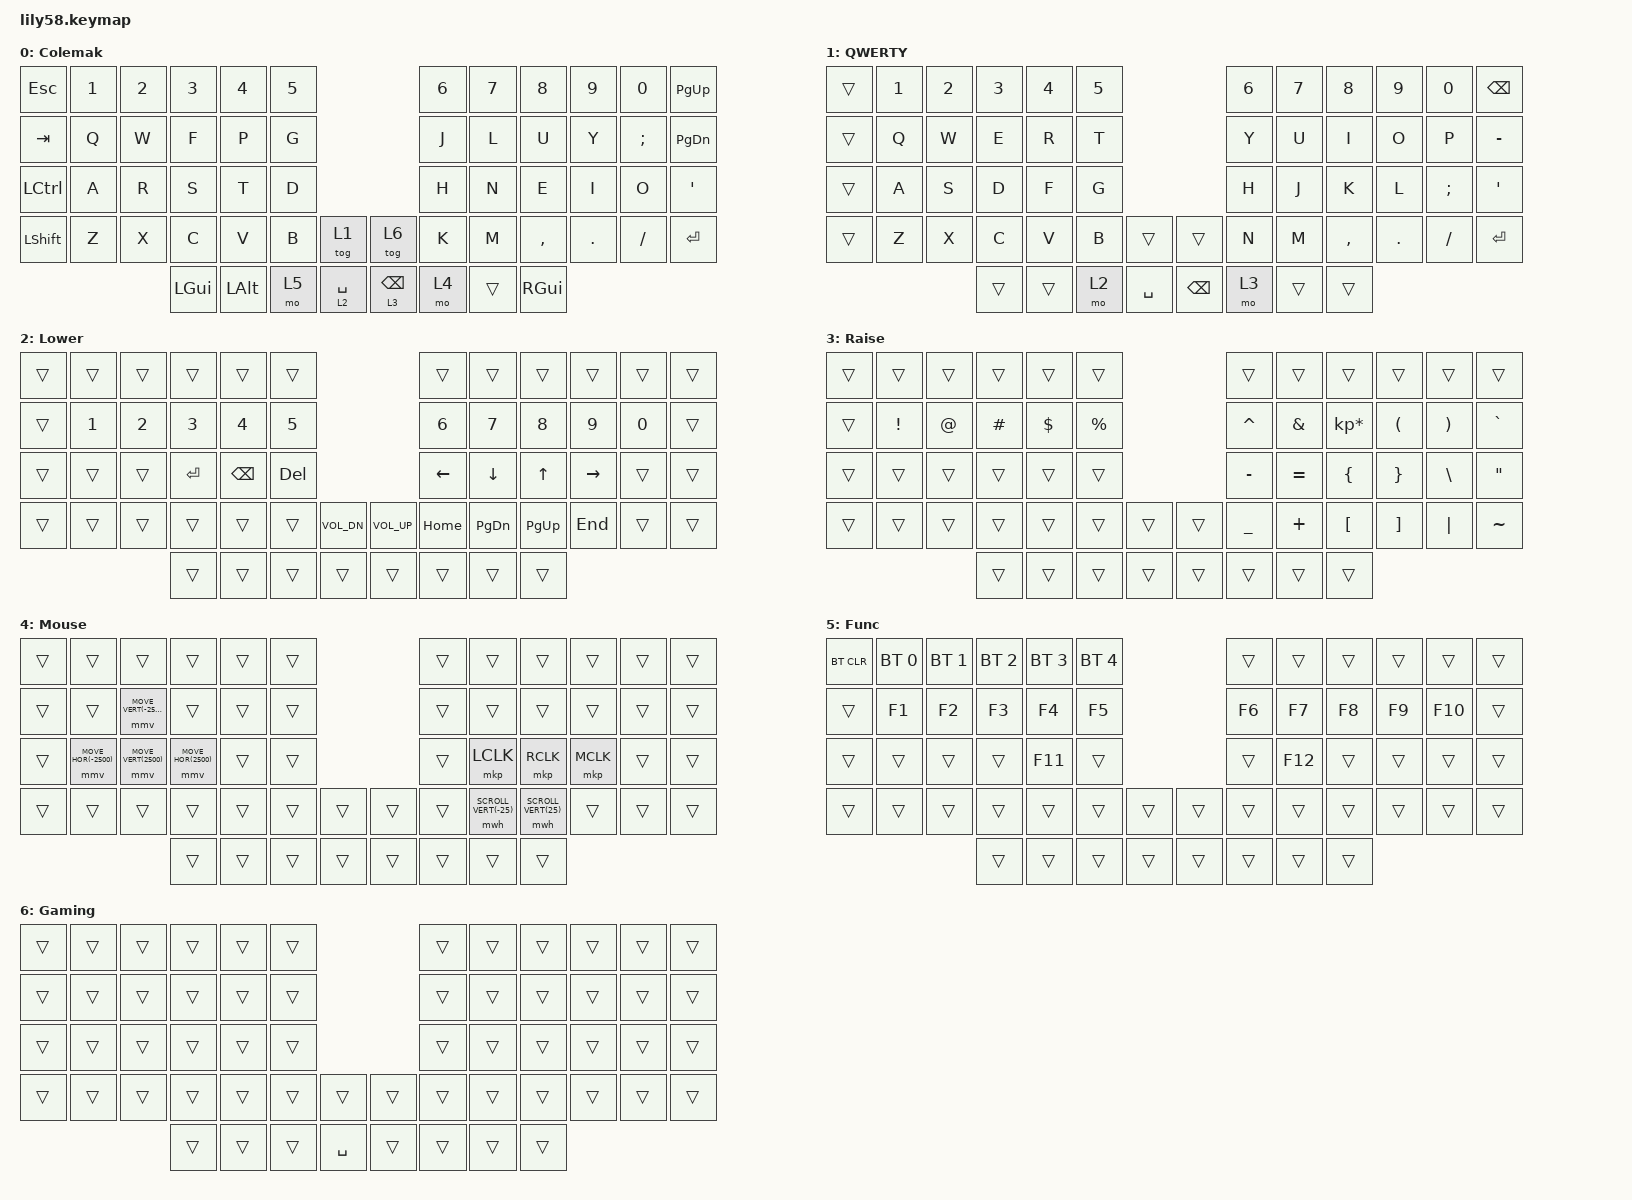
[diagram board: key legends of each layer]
/*
 * Copyright (c) 2020 The ZMK Contributors
 *
 * SPDX-License-Identifier: MIT
 */

#include <behaviors.dtsi>
#include <dt-bindings/zmk/keys.h>
#include <dt-bindings/zmk/bt.h>
#include <dt-bindings/zmk/ext_power.h>
#include <dt-bindings/zmk/mouse.h>

#define KEYS_L 0 1 2 3 4 5    16 17 18 19 20 21  32 33 34 35 36 37  48 49 50 51 52 53
#define KEYS_R 6 7 8 9 10 11  22 23 24 25 26 27  38 39 40 41 42 43  54 55 56 57 58 59
#define THUMBS 64 65 66 67 68 69 70 71 72 73

&mmv {
    time-to-max-speed-ms = <350>;
    acceleration-exponent = <1>;
};

&lt {
    flavor = "balanced";
    tapping-term-ms = <170>;
    quick-tap-ms = <170>;
    require-prior-idle-ms = <125>;
    retro-tap;
};

/ {
    keymap {
        compatible = "zmk,keymap";

        colemak_layer {
// ---------------------------------------------------------------------------------------------------------------
// |  ESC  |  1  |  2  |  3   |  4   |   5   |                     |   6   |   7   |  8   |  9   |   0   | PGUP  |
// |  TAB  |  Q  |  W  |  F   |  P   |   G   |                     |   J   |   L   |  U   |  Y   |   ;   | PGDN  |
// |  CTRL |  A  |  R  |  S   |  T   |   D   |                     |   H   |   N   |  E   |  I   |   O   |   '   |
// | SHIFT |  Z  |  X  |  C   |  V   |   B   | QWERTY |  |         |   K   |   M   |  ,   |  .   |   /   | ENTER |
//                     | LGUI | ALT  | LOWER | SPACE  |  |  BSPC   | RAISE | MOUSE | RGUI |
            label = "Colemak";
            bindings = <
&kp ESC   &kp N1 &kp N2 &kp N3   &kp N4   &kp N5                           &kp N6 &kp N7 &kp N8    &kp N9  &kp N0   &kp PG_UP
&kp TAB   &kp Q  &kp W  &kp F    &kp P    &kp G                            &kp J  &kp L  &kp U     &kp Y   &kp SEMI &kp PG_DN
&kp LCTRL &kp A  &kp R  &kp S    &kp T    &kp D                            &kp H  &kp N  &kp E     &kp I   &kp O    &kp SQT
&kp LSHFT &kp Z  &kp X  &kp C    &kp V    &kp B  &tog 1        &tog 6      &kp K  &kp M  &kp COMMA &kp DOT &kp FSLH &kp RET
                        &kp LGUI &kp LALT &mo 5  &lt 2 SPACE   &lt 3 BSPC  &mo 4  &trans &kp RGUI
            >;
        };

        qwerty_layer {
// ------------------------------------------------------------------------------------------------------------
// |       |  1  |  2  |  3   |  4   |  5   |                   |  6   |  7    |  8    |  9   |   0   | BSPC  |
// |       |  Q  |  W  |  E   |  R   |  T   |                   |  Y   |  U    |  I    |  O   |   P   |   -   |
// |       |  A  |  S  |  D   |  F   |  G   |                   |  H   |  J    |  K    |  L   |   ;   |   '   |
// |       |  Z  |  X  |  C   |  V   |  B   |        |  |       |  N   |  M    |  ,    |  .   |   /   |  RET  |
//                     |      |      |      |        |  |       |      |       |       |
            label = "QWERTY";
            bindings = <
&trans &kp N1 &kp N2 &kp N3 &kp N4 &kp N5                    &kp N6 &kp N7 &kp N8    &kp N9  &kp N0   &kp BSPC
&trans &kp Q  &kp W  &kp E  &kp R  &kp T                     &kp Y  &kp U  &kp I     &kp O   &kp P    &kp MINUS
&trans &kp A  &kp S  &kp D  &kp F  &kp G                     &kp H  &kp J  &kp K     &kp L   &kp SEMI &kp SQT
&trans &kp Z  &kp X  &kp C  &kp V  &kp B  &trans     &trans  &kp N  &kp M  &kp COMMA &kp DOT &kp FSLH &kp RET
                     &trans &trans &mo 2  &kp SPACE  &kp BSPC &mo 3 &trans &trans
            >;
        };

        lower_layer {
// -----------------------------------------------------------------------------------------------------------
// |       |     |     |      |     |     |                    |      |       |       |      |       |       |
// |       |  1  |  2  |  3   |  4  |  5  |                    |  6   |   7   |  8    |  9   |   0   |       |
// |       |  6  |  7  |  8   |  9  |  0  |                    |  <-  |   v   |  ^    | ->   |       |       |
// |       |     |     |  RET | BSPC| DEL | VOL_DN |  | VOL_UP | HOME | PGDN  | PGUP  | END  |       |       |
//                     |      |     |     |        |  |        |      |       |       |
            label = "Lower";
            bindings = <
&trans &trans &trans &trans  &trans   &trans                            &trans   &trans    &trans    &trans    &trans &trans
&trans &kp N1 &kp N2 &kp N3  &kp N4   &kp N5                            &kp N6   &kp N7    &kp N8    &kp N9    &kp N0 &trans
&trans &trans &trans &kp RET &kp BSPC &kp DEL                           &kp LEFT &kp DOWN  &kp UP    &kp RIGHT &trans &trans
&trans &trans &trans &trans  &trans   &trans  &kp C_VOL_DN &kp C_VOL_UP &kp HOME &kp PG_DN &kp PG_UP &kp END   &trans &trans
                     &trans  &trans   &trans  &trans       &trans       &trans   &trans    &trans
            >;
        };

        raise_layer {
// -----------------------------------------------------------------------------------------------------------
// | BTCLR |  BT1  |  BT2  |  BT3  |  BT4   | BT5  |                   |     |     |     |     |     |     |
// |       |   !   |   @   |   #   |   $    |  %   |                   |  ^  |  &  |  *  |  (  |  )  |  `  |
// |       |       |       |       |        |      |                   |  -  |  =  |  {  |  }  |  \  |  "  |
// |       |       |       |       |        |      |        |  |       |  _  |  +  |  [  |  ]  |  |  |  ~  |
//                         |       |        |      |        |  |       |     |     |     |
            label = "Raise";
            bindings = <
&trans &trans   &trans &trans   &trans     &trans                    &trans    &trans    &trans          &trans    &trans    &trans
&trans &kp EXCL &kp AT &kp HASH &kp DOLLAR &kp PRCNT                 &kp CARET &kp AMPS  &kp KP_MULTIPLY &kp LPAR  &kp RPAR  &kp GRAVE
&trans &trans   &trans &trans   &trans     &trans                    &kp MINUS &kp EQUAL &kp LBRC        &kp RBRC  &kp BSLH  &kp DQT 
&trans &trans   &trans &trans   &trans     &trans    &trans   &trans &kp UNDER &kp PLUS  &kp LBKT        &kp RBKT  &kp PIPE  &kp TILDE
                       &trans   &trans     &trans    &trans   &trans &trans    &trans    &trans
            >;
        };

        mouse_layer {
// -------------------------------------------------------------------------------------------------------
// |   |       |       |        |      |     |                   |      |      |      |       |     |    |
// |   |       |  MUP  |        |      |     |                   |      |      |      |       |     |    |
// |   | MLEFT | MDOWN | MRIGHT |      |     |                   |      | LCLK | RCLK |       |     |    |
// |   |       |       |        |      |     |        |  |       |      | SCRD | SCRU |       |     |    |
//                     |        |      |     |        |  |       |      |      |      |
           label = "Mouse";
           bindings = <
&trans &trans               &trans                &trans              &trans &trans                &trans &trans                &trans               &trans    &trans  &trans
&trans &trans               &mmv MOVE_VERT(-2500) &trans              &trans &trans                &trans &trans                &trans               &trans    &trans  &trans
&trans &mmv MOVE_HOR(-2500) &mmv MOVE_VERT(2500)  &mmv MOVE_HOR(2500) &trans &trans                &trans &mkp LCLK             &mkp RCLK            &mkp MCLK &trans  &trans
&trans &trans               &trans                &trans              &trans &trans &trans  &trans &trans &mwh SCROLL_VERT(-25) &mwh SCROLL_VERT(25) &trans    &trans  &trans
                                                  &trans              &trans &trans &trans  &trans &trans &trans                &trans
            >;
        };

        function_layer {
// --------------------------------------------------------------------------------------------------------
// |   |       |       |        |      |     |                   |       |      |      |       |     |    |
// |   |  F1   |  F2   |  F3    | F4   | F5  |                   |  F6   |  F7  | F8   |  F9   | F10 |    |
// |   |       |       |        | F11  |     |                   |       | F12  |      |       |     |    |
// |   |       |       |        |      |     |        |  |       |       |      |      |       |     |    |
//                     |        |      |     |        |  |       |       |      |      |
           label = "Func";
           bindings = <
&bt BT_CLR &bt BT_SEL 0 &bt BT_SEL 1  &bt BT_SEL 2  &bt BT_SEL 3 &bt BT_SEL 4                &trans  &trans  &trans &trans &trans  &trans
&trans     &kp F1       &kp F2        &kp F3        &kp F4       &kp F5                      &kp F6  &kp F7  &kp F8 &kp F9 &kp F10 &trans
&trans     &trans       &trans        &trans        &kp F11      &trans                      &trans  &kp F12 &trans &trans &trans  &trans
&trans     &trans       &trans        &trans        &trans       &trans       &trans  &trans &trans  &trans  &trans &trans &trans  &trans
                                      &trans        &trans       &trans       &trans  &trans &trans  &trans  &trans
            >;
        };

        gaming_layer {
// --------------------------------------------------------------------------------------------------------
// |   |       |       |        |      |     |                   |       |      |      |       |     |    |
// |   |  F1   |  F2   |  F3    | F4   | F5  |                   |  F6   |  F7  | F8   |  F9   | F10 |    |
// |   |       |       |        | F11  |     |                   |       | F12  |      |       |     |    |
// |   |       |       |        |      |     |        |  |       |       |      |      |       |     |    |
//                     |        |      |     |        |  |       |       |      |      |
           label = "Gaming";
           bindings = <
&trans     &trans       &trans        &trans        &trans       &trans                      &trans  &trans  &trans &trans &trans  &trans
&trans     &trans       &trans        &trans        &trans       &trans                      &trans  &trans  &trans &trans &trans  &trans
&trans     &trans       &trans        &trans        &trans       &trans                      &trans  &trans  &trans &trans &trans  &trans
&trans     &trans       &trans        &trans        &trans       &trans       &trans  &trans &trans  &trans  &trans &trans &trans  &trans
                                      &trans        &trans       &trans       &kp SPACE  &trans &trans  &trans  &trans
            >;
        };
    };
};
